# CH32M030 register map
Vendor: WCH Ltd.; File version: 1.1
Registers are 32-bit, read-write, reset 0x0 unless marked. A register's access mark holds for its fields unless they carry their own. Offsets are from the block's base; [hi:lo] are bit positions.

## SPI1 — Serial peripheral interface
Base 0x40013000
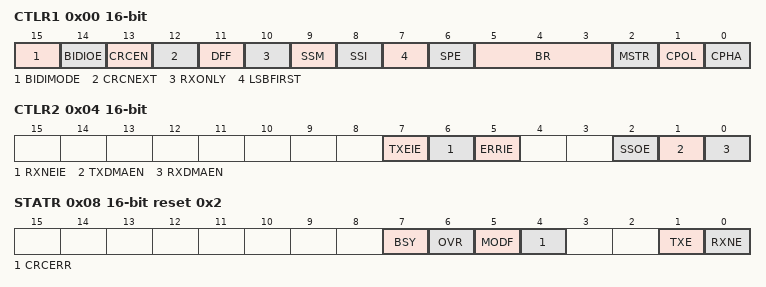
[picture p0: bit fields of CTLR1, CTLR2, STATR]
0x00 CTLR1 16-bit — control register 1
  [15] BIDIMODE — Bidirectional data mode enable
  [14] BIDIOE — Output enable in bidirectional mode
  [13] CRCEN — Hardware CRC calculation enable
  [12] CRCNEXT — CRC transfer next
  [11] DFF — Data frame format
  [10] RXONLY — Receive only
  [9] SSM — Software slave management
  [8] SSI — Internal slave select
  [7] LSBFIRST — Frame format
  [6] SPE — SPI enable
  [5:3] BR — Baud rate control
  [2] MSTR — Master selection
  [1] CPOL — Clock polarity
  [0] CPHA — Clock phase
0x04 CTLR2 16-bit — control register 2
  [7] TXEIE — Tx buffer empty interrupt enable
  [6] RXNEIE — RX buffer not empty interrupt enable
  [5] ERRIE — Error interrupt enable
  [2] SSOE — SS output enable
  [1] TXDMAEN — Tx buffer DMA enable
  [0] RXDMAEN — Rx buffer DMA enable
0x08 STATR 16-bit access per field reset 0x2 — status register
  [7] BSY ro — Busy flag
  [6] OVR ro — Overrun flag
  [5] MODF ro — Mode fault
  [4] CRCERR rw — CRC error flag
  [1] TXE ro — Transmit buffer empty
  [0] RXNE ro — Receive buffer not empty
0x0C DATAR 16-bit — data register
  [15:0] DATAR — Data register
0x10 CRCR 16-bit reset 0x7 — CRCR polynomial register
  [15:0] CRCPOLY — CRC polynomial register
0x14 RCRCR 16-bit ro — RX CRC register
  [15:0] RxCRC
0x18 TCRCR 16-bit ro — TX CRC register
  [15:0] TXCRC
0x24 HSCR 16-bit wo — High speed control register
  [0] HSRXEN — High speed read mode enable bit

## USBPD0 — USBPD configuration
Base 0x40024000
Same registers: USBPD1 0x40024400
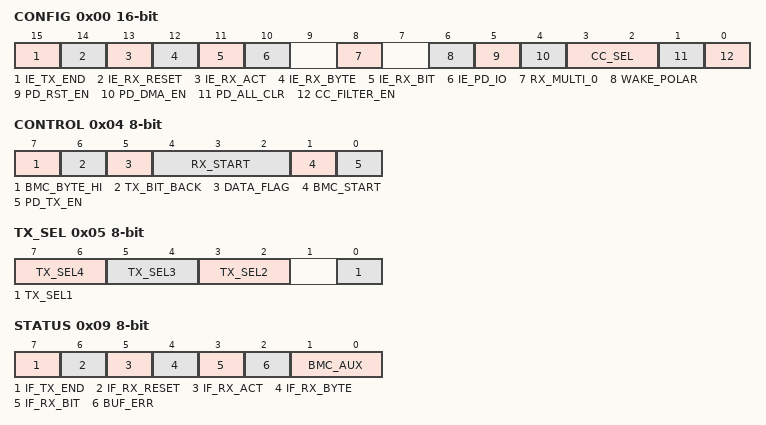
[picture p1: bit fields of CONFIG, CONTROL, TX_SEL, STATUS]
0x00 CONFIG 16-bit access per field — PD interrupt enable register
  [15] IE_TX_END rw — transfer complete register
  [14] IE_RX_RESET rw — Receive complete rst register
  [13] IE_RX_ACT rw — Receive complete register
  [12] IE_RX_BYTE rw — Receive byte register
  [11] IE_RX_BIT rw — bit interrupt Enable
  [10] IE_PD_IO rw — IO Enable
  [8] RX_MULTI_0 ro — Several consecutive 0 indicator bits are received
  [6] WAKE_POLAR rw — wakeup polarity
  [5] PD_RST_EN rw — PD RST Enable
  [4] PD_DMA_EN rw — PD DMA Enable
  [3:2] CC_SEL rw — PD Commutation port
  [1] PD_ALL_CLR rw — PD ITClear
  [0] CC_FILTER_EN rw — PIN filtering enabled
0x02 BMC_CLK_CNT 16-bit — BMC sampling clock counter
  [8:0] BMC_CLK_CNT — R/T counter
0x04 CONTROL 8-bit access per field — PD Send and receive enable register
  [7] BMC_BYTE_HI ro — BMC_BYTE_HI value
  [6] TX_BIT_BACK ro — TX_BIT_BACK value
  [5] DATA_FLAG ro — DATA_FLAG value
  [4:2] RX_START ro — PD receive status identification
  [1] BMC_START rw — BMC_START value
  [0] PD_TX_EN rw — PD_TX_EN value
0x05 TX_SEL 8-bit — SOP port selection register
  [7:6] TX_SEL4 — K-CODE4 type selection
  [5:4] TX_SEL3 — K-CODE3 type selection
  [3:2] TX_SEL2 — K-CODE2 type selection
  [0] TX_SEL1 — K-CODE1 type selection
0x06 BMC_TX_SZ 16-bit — PD send length register
  [8:0] BMC_TX_SZ — BMC_TX_SZ value
0x08 DATA_BUF 8-bit ro — DMA cache data register
  [7:0] DATA_BUF — DATA_BUF value
0x09 STATUS 8-bit access per field — PD interrupt flag register
  [7] IF_TX_END rw — IF_TX_END value
  [6] IF_RX_RESET rw — IF_RX_RESET value
  [5] IF_RX_ACT rw — IF_RX_ACT value
  [4] IF_RX_BYTE rw — IF_RX_BYTE value
  [3] IF_RX_BIT rw — IF_RX_BIT value
  [2] BUF_ERR rw — BUF_ERR value
  [1:0] BMC_AUX ro — BMC_AUX value
0x0A BMC_BYTE_CNT 16-bit ro — Byte counter
  [8:0] BMC_BYTE_CNT — BMC_BYTE_CNT value
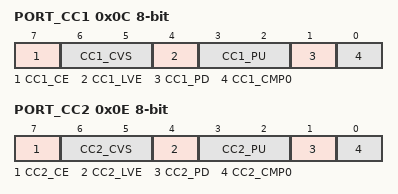
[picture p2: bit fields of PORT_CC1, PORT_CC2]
0x0C PORT_CC1 8-bit access per field — CC1 port control register
  [7] CC1_CE rw — CC1 voltage comparator enable
  [6:5] CC1_CVS rw — CC1 voltage comparator reference voltage
  [4] CC1_LVE rw — CC1 port output of the low voltage
  [3:2] CC1_PU rw — CC1 port pull-up current selection
  [1] CC1_PD rw — CC1 port pull-down resistor enable
  [0] CC1_CMP0 ro — CC1 output of the voltage comparator
0x0E PORT_CC2 8-bit access per field — CC2 port control register
  [7] CC2_CE rw — CC2 voltage comparator enable
  [6:5] CC2_CVS rw — CC2 voltage comparator reference voltage
  [4] CC2_LVE rw — CC2 port output of the low voltage
  [3:2] CC2_PU rw — CC2 port pull-up current selection
  [1] CC2_PD rw — CC2 port pull-down resistor enable
  [0] CC2_CMP0 ro — CC2 output of the voltage comparator
0x10 DMA 16-bit — PD buffer start address register
  [11:0] USBPD_DMA_ADDR — USBPD_DMA_ADDR value
